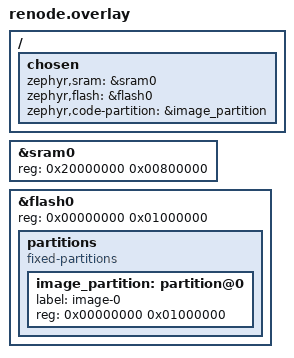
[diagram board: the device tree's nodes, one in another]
/*
 * Variant #1 (Renode): virtually enlarged memory, so that models also run that do not
 * fit the real nRF5340 (1 MB flash / 512 KB RAM).
 * Must match renode/cortex_m33_profiler.repl (same addresses and sizes)!
 */

/ {
	chosen {
		zephyr,sram = &sram0;
		zephyr,flash = &flash0;
		zephyr,code-partition = &image_partition;
	};
};

/* 1. Enlarge RAM to 8 MB */
&sram0 {
	reg = <0x20000000 0x00800000>; /* 8 MB virtual SRAM */
};

/* 2. Enlarge flash to 16 MB and adjust the partitions */
&flash0 {
	reg = <0x00000000 0x01000000>; /* 16 MB virtual flash */

	partitions {
		compatible = "fixed-partitions";
		#address-cells = <1>;
		#size-cells = <1>;

		/* The whole range as one image partition */
		image_partition: partition@0 {
			label = "image-0";
			reg = <0x00000000 0x01000000>;
		};
	};
};
